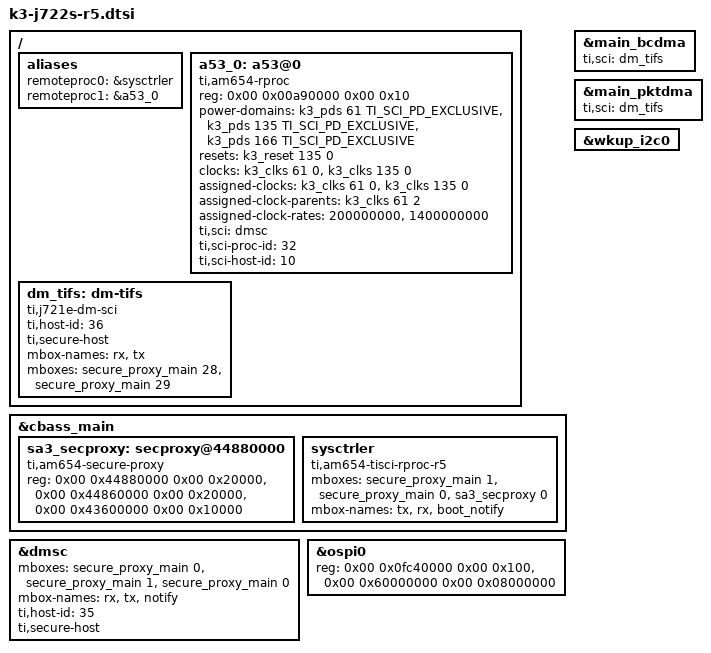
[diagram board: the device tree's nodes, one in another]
// SPDX-License-Identifier: GPL-2.0
/*
 * J722S common DTSI file for R5 SPL
 * Copyright (C) 2024 Texas Instruments Incorporated - https://www.ti.com/
 * Copyright (c) 2025 TQ-Systems GmbH <u-boot@ew.tq-group.com>, D-82229 Seefeld, Germany.
 * Author: Matthias Schiffer
 */

/ {
	aliases {
		remoteproc0 = &sysctrler;
		remoteproc1 = &a53_0;
	};

	a53_0: a53@0 {
		bootph-pre-ram;
		compatible = "ti,am654-rproc";
		reg = <0x00 0x00a90000 0x00 0x10>;
		power-domains = <&k3_pds 61 TI_SCI_PD_EXCLUSIVE>,
				<&k3_pds 135 TI_SCI_PD_EXCLUSIVE>,
				<&k3_pds 166 TI_SCI_PD_EXCLUSIVE>;
		resets = <&k3_reset 135 0>;
		clocks = <&k3_clks 61 0>, <&k3_clks 135 0>;
		clock-names = "gtc", "core";
		assigned-clocks = <&k3_clks 61 0>, <&k3_clks 135 0>;
		assigned-clock-parents = <&k3_clks 61 2>;
		assigned-clock-rates = <200000000>, <1400000000>;
		ti,sci = <&dmsc>;
		ti,sci-proc-id = <32>;
		ti,sci-host-id = <10>;
	};

	dm_tifs: dm-tifs {
		bootph-all;
		compatible = "ti,j721e-dm-sci";
		ti,host-id = <36>;
		ti,secure-host;
		mbox-names = "rx", "tx";
		mboxes = <&secure_proxy_main 28>,
			 <&secure_proxy_main 29>;
	};
};

&cbass_main {
	sa3_secproxy: secproxy@44880000 {
		bootph-all;
		compatible = "ti,am654-secure-proxy";
		#mbox-cells = <1>;
		reg = <0x00 0x44880000 0x00 0x20000>,
		      <0x00 0x44860000 0x00 0x20000>,
		      <0x00 0x43600000 0x00 0x10000>;
		reg-names = "rt", "scfg", "target_data";
	};

	sysctrler: sysctrler {
		bootph-all;
		compatible = "ti,am654-tisci-rproc-r5";
		mboxes = <&secure_proxy_main 1>,
			 <&secure_proxy_main 0>,
			 <&sa3_secproxy 0>;
		mbox-names = "tx", "rx", "boot_notify";
	};
};

&dmsc {
	bootph-pre-ram;
	mboxes = <&secure_proxy_main 0>,
		 <&secure_proxy_main 1>,
		 <&secure_proxy_main 0>;
	mbox-names = "rx", "tx", "notify";
	ti,host-id = <35>;
	ti,secure-host;
};

&main_bcdma {
	ti,sci = <&dm_tifs>;
};

&main_pktdma {
	ti,sci = <&dm_tifs>;
};

&ospi0 {
	reg = <0x00 0x0fc40000 0x00 0x100>,
	      <0x00 0x60000000 0x00 0x08000000>;
};

&wkup_i2c0 {
	/delete-property/ power-domains;
};
